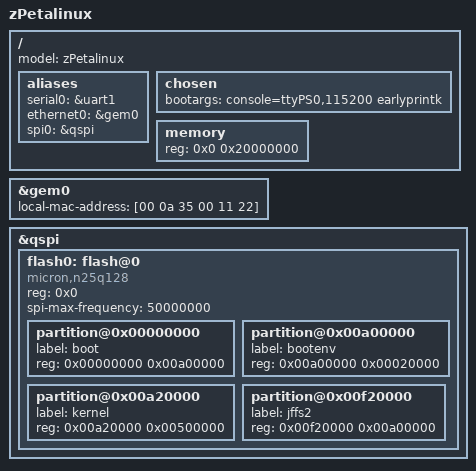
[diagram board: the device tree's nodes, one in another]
/*
 * CAUTION: This file is automatically generated by PetaLinux SDK.
 * DO NOT modify this file
 */

/include/ "skeleton.dtsi"
/include/ "zynq-7000.dtsi"
/include/ "pcw.dtsi"

/ {
	model = "zPetalinux";
	aliases {
		serial0 = &uart1;
		ethernet0 = &gem0;
		spi0 = &qspi;
	};
	chosen {
		bootargs = "console=ttyPS0,115200 earlyprintk";
	};
	memory {
		device_type = "memory";
		reg = <0x0 0x20000000>;
	};
};

&gem0 {
	local-mac-address = [00 0a 35 00 11 22];
};

&qspi {
	#address-cells = <1>;
	#size-cells = <0>;
	flash0: flash@0 {
		compatible = "micron,n25q128";
		reg = <0x0>;
		#address-cells = <1>;
		#size-cells = <1>;
		spi-max-frequency = <50000000>;
		partition@0x00000000 {
			label = "boot";
			reg = <0x00000000 0x00a00000>;
		};
		partition@0x00a00000 {
			label = "bootenv";
			reg = <0x00a00000 0x00020000>;
		};
		partition@0x00a20000 {
			label = "kernel";
			reg = <0x00a20000 0x00500000>;
		};
		partition@0x00f20000 {
			label = "jffs2";
			reg = <0x00f20000 0x00a00000>;
		};
	};
};

